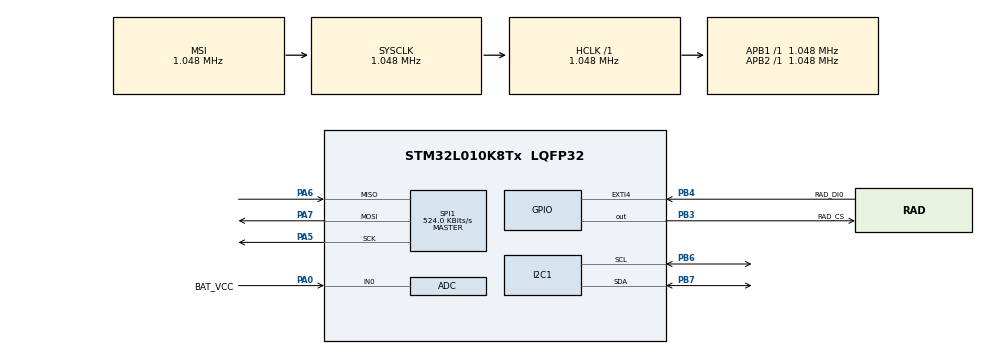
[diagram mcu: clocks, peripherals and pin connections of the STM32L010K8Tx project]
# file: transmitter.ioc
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ADC.ClockPrescaler=ADC_CLOCK_SYNC_PCLK_DIV4
ADC.SamplingTime=ADC_SAMPLETIME_19CYCLES_5
I2C1.Timing=0x00000202
Mcu.Family=STM32L0
Mcu.Name=STM32L010K8Tx
Mcu.Package=LQFP32
NVIC.ADC1_IRQn=true\:0\:0\:false\:false\:true\:true\:true\:true
NVIC.EXTI4_15_IRQn=true\:0\:0\:false\:false\:true\:true\:true\:true
NVIC.RTC_IRQn=true\:0\:0\:false\:false\:true\:true\:true\:true
PA0.GPIO_Label=BAT_VCC
PA0.Mode=IN0
PA0.Signal=ADC_IN0
PA5.Mode=Full_Duplex_Master
PA5.Signal=SPI1_SCK
PA6.Mode=Full_Duplex_Master
PA6.Signal=SPI1_MISO
PA7.Mode=Full_Duplex_Master
PA7.Signal=SPI1_MOSI
PB3.GPIO_Label=RAD_CS
PB3.Signal=GPIO_Output
PB4.GPIO_Label=RAD_DI0
PB4.Signal=GPXTI4
PB6.Mode=I2C
PB6.Signal=I2C1_SCL
PB7.Mode=I2C
PB7.Signal=I2C1_SDA
PC14-OSC32_IN.Mode=LSE-External-Oscillator
PC14-OSC32_IN.Signal=RCC_OSC32_IN
PC15-OSC32_OUT.Mode=LSE-External-Oscillator
PC15-OSC32_OUT.Signal=RCC_OSC32_OUT
ProjectManager.HeapSize=0x200
ProjectManager.StackSize=0x400
ProjectManager.TargetToolchain=CMake
RCC.AHBFreq_Value=1048000
RCC.APB1Freq_Value=1048000
RCC.APB1TimFreq_Value=1048000
RCC.APB2Freq_Value=1048000
RCC.APB2TimFreq_Value=1048000
RCC.HCLKFreq_Value=1048000
RCC.HSI16_VALUE=16000000
RCC.HSI_VALUE=16000000
RCC.MSIClockRange=RCC_MSIRANGE_4
RCC.MSI_VALUE=1048000
RCC.RTCClockSelectionVirtual=RCC_RTCCLKSOURCE_LSE
RCC.SYSCLKFreq_VALUE=1048000
RCC.VCOOutputFreq_Value=48000000
RTC.WakeUpClock=RTC_WAKEUPCLOCK_CK_SPRE_16BITS
RTC.WakeUpCounter=54
SPI1.CalculateBaudRate=524.0 KBits/s
SPI1.Direction=SPI_DIRECTION_2LINES
SPI1.Mode=SPI_MODE_MASTER
SPI1.VirtualType=VM_MASTER
TIM2.Period=9999
TIM2.Prescaler=31
VP_RTC_VS_RTC_Activate.Mode=RTC_Enabled
VP_RTC_VS_RTC_Calendar.Mode=RTC_Calendar
VP_RTC_VS_RTC_WakeUp_intern.Mode=WakeUp
VP_TIM2_VS_ClockSourceINT.Mode=Internal
board=custom

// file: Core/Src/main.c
/* USER CODE BEGIN Header */
/**
 ******************************************************************************
 * @file           : main.c
 * @brief          : Main program body
 ******************************************************************************
 * @attention
 *
 * Copyright (c) 2025 STMicroelectronics.
 * All rights reserved.
 *
 * This software is licensed under terms that can be found in the LICENSE file
 * in the root directory of this software component.
 * If no LICENSE file comes with this software, it is provided AS-IS.
 *
 ******************************************************************************
 */
/* USER CODE END Header */
#include "main.h"
#include "adc.h"
#include "i2c.h"
#include "rtc.h"
#include "spi.h"
#include "tim.h"
#include "gpio.h"

/* USER CODE BEGIN Includes */

#include "app/app.h"
#include <string.h>

/* USER CODE END Includes */

/* USER CODE BEGIN PV */

app_handle app;

/* USER CODE END PV */

void SystemClock_Config(void);

int main(void)
{

  /* MCU Configuration--------------------------------------------------------*/

  /* Reset of all peripherals, Initializes the Flash interface and the Systick. */
  HAL_Init();

  /* Configure the system clock */
  SystemClock_Config();

  /* Initialize all configured peripherals */
  MX_GPIO_Init();
  MX_RTC_Init();
  MX_SPI1_Init();
  MX_TIM2_Init();
  MX_ADC_Init();
  MX_I2C1_Init();

  /* Infinite loop */
  /* USER CODE BEGIN WHILE */

  memset(&app, 0, sizeof(app));
  app_init(&app, SystemClock_Config);

  while (1)
  {
    app_loop(&app);

    /* USER CODE END WHILE */

  }
}

void SystemClock_Config(void)
{
  RCC_OscInitTypeDef RCC_OscInitStruct = {0};
  RCC_ClkInitTypeDef RCC_ClkInitStruct = {0};
  RCC_PeriphCLKInitTypeDef PeriphClkInit = {0};

  /** Configure the main internal regulator output voltage
  */
  __HAL_PWR_VOLTAGESCALING_CONFIG(PWR_REGULATOR_VOLTAGE_SCALE1);

  /** Configure LSE Drive Capability
  */
  HAL_PWR_EnableBkUpAccess();
  __HAL_RCC_LSEDRIVE_CONFIG(RCC_LSEDRIVE_LOW);

  /** Initializes the RCC Oscillators according to the specified parameters
  * in the RCC_OscInitTypeDef structure.
  */
  RCC_OscInitStruct.OscillatorType = RCC_OSCILLATORTYPE_LSE|RCC_OSCILLATORTYPE_MSI;
  RCC_OscInitStruct.LSEState = RCC_LSE_ON;
  RCC_OscInitStruct.MSIState = RCC_MSI_ON;
  RCC_OscInitStruct.MSICalibrationValue = 0;
  RCC_OscInitStruct.MSIClockRange = RCC_MSIRANGE_4;
  RCC_OscInitStruct.PLL.PLLState = RCC_PLL_NONE;
  if (HAL_RCC_OscConfig(&RCC_OscInitStruct) != HAL_OK)
  {
    Error_Handler();
  }

  /** Initializes the CPU, AHB and APB buses clocks
  */
  RCC_ClkInitStruct.ClockType = RCC_CLOCKTYPE_HCLK|RCC_CLOCKTYPE_SYSCLK
                              |RCC_CLOCKTYPE_PCLK1|RCC_CLOCKTYPE_PCLK2;
  RCC_ClkInitStruct.SYSCLKSource = RCC_SYSCLKSOURCE_MSI;
  RCC_ClkInitStruct.AHBCLKDivider = RCC_SYSCLK_DIV1;
  RCC_ClkInitStruct.APB1CLKDivider = RCC_HCLK_DIV1;
  RCC_ClkInitStruct.APB2CLKDivider = RCC_HCLK_DIV1;

  if (HAL_RCC_ClockConfig(&RCC_ClkInitStruct, FLASH_LATENCY_0) != HAL_OK)
  {
    Error_Handler();
  }
  PeriphClkInit.PeriphClockSelection = RCC_PERIPHCLK_I2C1|RCC_PERIPHCLK_RTC;
  PeriphClkInit.I2c1ClockSelection = RCC_I2C1CLKSOURCE_PCLK1;
  PeriphClkInit.RTCClockSelection = RCC_RTCCLKSOURCE_LSE;
  if (HAL_RCCEx_PeriphCLKConfig(&PeriphClkInit) != HAL_OK)
  {
    Error_Handler();
  }
}

/* USER CODE BEGIN 4 */

void HAL_ADC_ConvCpltCallback(ADC_HandleTypeDef *hadc)
{
  app_adc_conv_cplt_callback(&app, hadc);
}

void HAL_GPIO_EXTI_Callback(uint16_t GPIO_Pin)
{
  app_gpio_exti_callback(&app, GPIO_Pin);
}

/* USER CODE END 4 */

void Error_Handler(void)
{
  __disable_irq();
  while (1)
  {
  }
}
